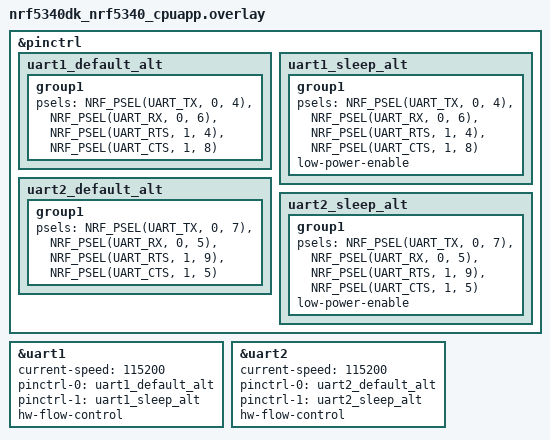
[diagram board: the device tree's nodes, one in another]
/*
 * Copyright (c) 2026 Nordic Semiconductor ASA
 *
 * SPDX-License-Identifier: LicenseRef-Nordic-5-Clause
 */

/*
 * Required loopbacks:
 * P0.04 <-> P0.05
 * P0.06 <-> P0.07
 * P1.04 <-> P1.05
 * P1.08 <-> P1.09
 */

&pinctrl {
	uart1_default_alt: uart1_default_alt {
		group1 {
			psels = <NRF_PSEL(UART_TX, 0, 4)>,
				<NRF_PSEL(UART_RX, 0, 6)>,
				<NRF_PSEL(UART_RTS, 1, 4)>,
				<NRF_PSEL(UART_CTS, 1, 8)>;
		};
	};

	uart1_sleep_alt: uart1_sleep_alt {
		group1 {
			psels = <NRF_PSEL(UART_TX, 0, 4)>,
				<NRF_PSEL(UART_RX, 0, 6)>,
				<NRF_PSEL(UART_RTS, 1, 4)>,
				<NRF_PSEL(UART_CTS, 1, 8)>;
			low-power-enable;
		};
	};

	uart2_default_alt: uart2_default_alt {
		group1 {
			psels = <NRF_PSEL(UART_TX, 0, 7)>,
				<NRF_PSEL(UART_RX, 0, 5)>,
				<NRF_PSEL(UART_RTS, 1, 9)>,
				<NRF_PSEL(UART_CTS, 1, 5)>;
		};
	};

	uart2_sleep_alt: uart2_sleep_alt {
		group1 {
			psels = <NRF_PSEL(UART_TX, 0, 7)>,
				<NRF_PSEL(UART_RX, 0, 5)>,
				<NRF_PSEL(UART_RTS, 1, 9)>,
				<NRF_PSEL(UART_CTS, 1, 5)>;
			low-power-enable;
		};
	};
};

dut_uart_a: &uart1 {
	status = "okay";
	current-speed = <115200>;
	pinctrl-0 = <&uart1_default_alt>;
	pinctrl-1 = <&uart1_sleep_alt>;
	pinctrl-names = "default", "sleep";
	hw-flow-control;
};

dut_uart_b: &uart2 {
	status = "okay";
	current-speed = <115200>;
	pinctrl-0 = <&uart2_default_alt>;
	pinctrl-1 = <&uart2_sleep_alt>;
	pinctrl-names = "default", "sleep";
	hw-flow-control;
};
